# FM33LG0XX register map
File version: 1.0
CPU: SC000 r1p0, little endian, no MPU, no FPU, 3 interrupt priority bits
Registers are 32-bit, read-write, reset 0x0 unless marked. A register's access mark holds for its fields unless they carry their own. Offsets are from the block's base; [hi:lo] are bit positions.

## PMU — PMU module information
Base 0x40002000
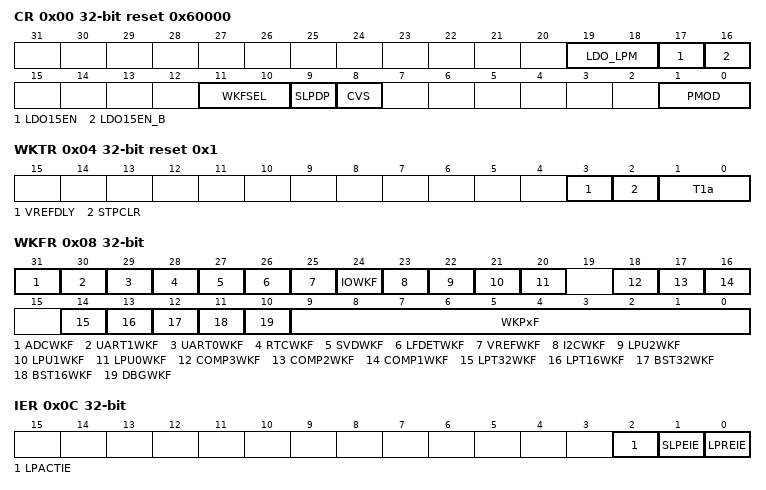
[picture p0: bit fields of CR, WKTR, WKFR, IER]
0x00 CR access per field reset 0x60000 — Power Management Control Register
  [19:18] LDO_LPM rw — LDO_LPM field description
  [17] LDO15EN ro — LDO15EN field description
  [16] LDO15EN_B ro — LDO15EN_B field description
  [11:10] WKFSEL rw — WKFSEL field description
  [9] SLPDP rw — SLPDP field description
  [8] CVS rw — CVS field description
  [1:0] PMOD rw — PMOD field description
0x04 WKTR reset 0x1 — Wakeup Time Register
  [3] VREFDLY — VREFDLY field description
  [2] STPCLR — STPCLR field description
  [1:0] T1a — T1a field description
0x08 WKFR access per field — Wakeup Source Flags Register
  [31] ADCWKF ro — ADCWKF field description
  [30] UART1WKF ro — UART1WKF field description
  [29] UART0WKF ro — UART0WKF field description
  [28] RTCWKF ro — RTCWKF field description
  [27] SVDWKF ro — SVDWKF field description
  [26] LFDETWKF ro — LFDETWKF field description
  [25] VREFWKF ro — VREFWKF field description
  [24] IOWKF ro — IOWKF field description
  [23] I2CWKF ro — I2CWKF field description
  [22] LPU2WKF ro — LPU2WKF field description
  [21] LPU1WKF ro — LPU1WKF field description
  [20] LPU0WKF ro — LPU0WKF field description
  [18] COMP3WKF ro — COMP3WKF field description
  [17] COMP2WKF ro — COMP2WKF field description
  [16] COMP1WKF ro — COMP1WKF field description
  [14] LPT32WKF ro — LPT32WKF field description
  [13] LPT16WKF ro — LPT16WKF field description
  [12] BST32WKF ro — BST32WKF field description
  [11] BST16WKF ro — BST16WKF field description
  [10] DBGWKF rw — DBGWKF field description
  [9:0] WKPxF rw — WKPxF field description
0x0C IER — PMU Interrupt Enable Register
  [2] LPACTIE — LPACTIE field description
  [1] SLPEIE — SLPEIE field description
  [0] LPREIE — LPREIE field description
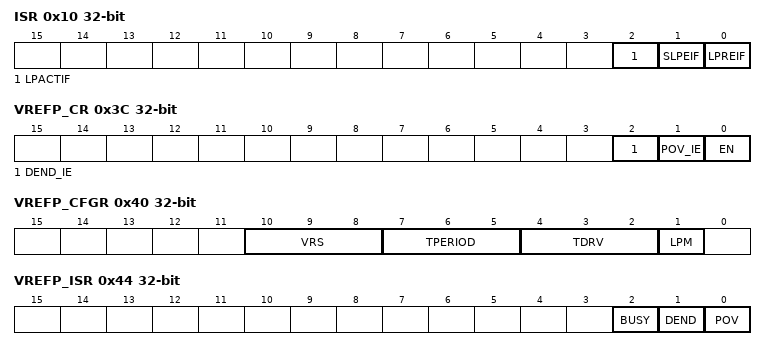
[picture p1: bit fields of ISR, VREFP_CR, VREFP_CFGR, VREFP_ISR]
0x10 ISR — PMU Interrupt and Status Register
  [2] LPACTIF — LPACTIF field description
  [1] SLPEIF — SLPEIF field description
  [0] LPREIF — LPREIF field description
0x38 ULPB_TR reset 0x10 — ULPBG trim Register
  [4:0] ULPBG_TRIM — ULPBG_TRIM field description
0x3C VREFP_CR — VREFP Control Register
  [2] DEND_IE — DEND_IE field description
  [1] POV_IE — POV_IE field description
  [0] EN — EN field description
0x40 VREFP_CFGR — VREFP Config Register
  [10:8] VRS — VRS field description
  [7:5] TPERIOD — TPERIOD field description
  [4:2] TDRV — TDRV field description
  [1] LPM — LPM field description
0x44 VREFP_ISR access per field — VREFP Interrupt Status Register
  [2] BUSY ro — BUSY field description
  [1] DEND rw — DEND field description
  [0] POV rw — POV field description
0x48 VREFP_TR reset 0x80 — VREFP Trim Register
  [7:0] TRIM — TRIM field description

## VREF — VREF module information
Base 0x4001A400
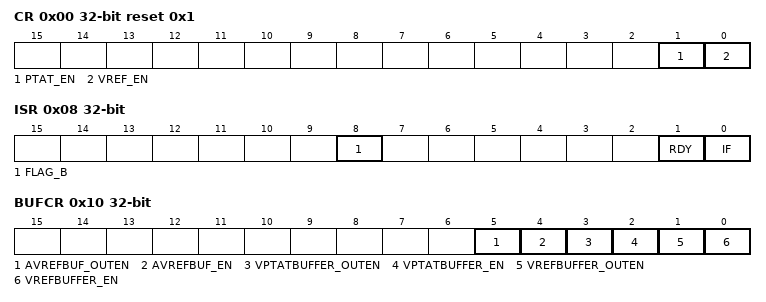
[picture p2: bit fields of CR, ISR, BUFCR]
0x00 CR reset 0x1 — VREF Control Register
  [1] PTAT_EN — PTAT_EN field description
  [0] VREF_EN — VREF_EN field description
0x04 CFGR — VREF Config Register
  [1:0] ST_DELAY — ST_DELAY field description
0x08 ISR access per field — VREF Status Register
  [8] FLAG_B ro — FLAG_B field description
  [1] RDY ro — RDY field description
  [0] IF rw — IF field description
0x0C IER — VREF Interrupt Enable Register
  [0] IE — IE field description
0x10 BUFCR — Buffer Control Register
  [5] AVREFBUF_OUTEN — AVREFBUF_OUTEN field description
  [4] AVREFBUF_EN — AVREFBUF_EN field description
  [3] VPTATBUFFER_OUTEN — VPTATBUFFER_OUTEN field description
  [2] VPTATBUFFER_EN — VPTATBUFFER_EN field description
  [1] VREFBUFFER_OUTEN — VREFBUFFER_OUTEN field description
  [0] VREFBUFFER_EN — VREFBUFFER_EN field description

## VAO — VAO module information
Base 0x4001F000
0x800 RST_CR — VBAT Reset Control Register
  [0] VBAT_RST — VBAT_RST field description
0x804 XTLF_CR — XTLF Control Register
  [3:0] XTLFEN — XTLFEN field description
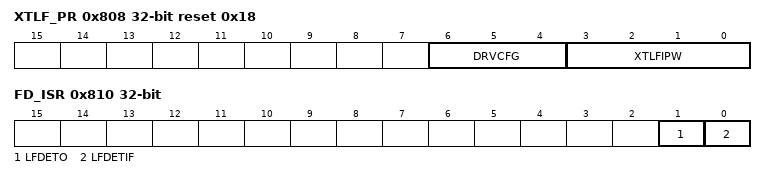
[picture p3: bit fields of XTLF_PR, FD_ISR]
0x808 XTLF_PR reset 0x18 — XTLF Power Register
  [6:4] DRVCFG — DRVCFG field description
  [3:0] XTLFIPW — XTLFIPW field description
0x80C FD_IER — XTLF Oscillation Fail Detection Interrupt Enable Register
  [0] LFDET_IE — LFDET_IE field description
0x810 FD_ISR access per field — XTLF Oscillation Fail Detection Interrupt Status Register
  [1] LFDETO ro — LFDETO field description
  [0] LFDETIF rw — LFDETIF field description
0xC00 INEN — VAO IO Input Enable Register
  [15] PHINEN — PHINEN field description
0xC04 PUEN — VAO IO Pull-up Enable Register
  [15] PHPUEN — PHPUEN field description
0xC08 ODEN — VAO IO Open Drain Enable Register
  [15] PHODEN — PHODEN field description
0xC0C FCR — VAO IO Function Control Register
  [31:30] PHFCR — PHFCR field description
0xC10 DOR — VAO IO Data Output Register
  [15] PHDO — PHDO field description
0xC14 DIR — VAO IO Data Input Register
  [15] PHDIN — PHDIN field description
0xC18 VILR — VAO IO Voltage Input Low Register
  [15] PHVIL — PHVIL field description
